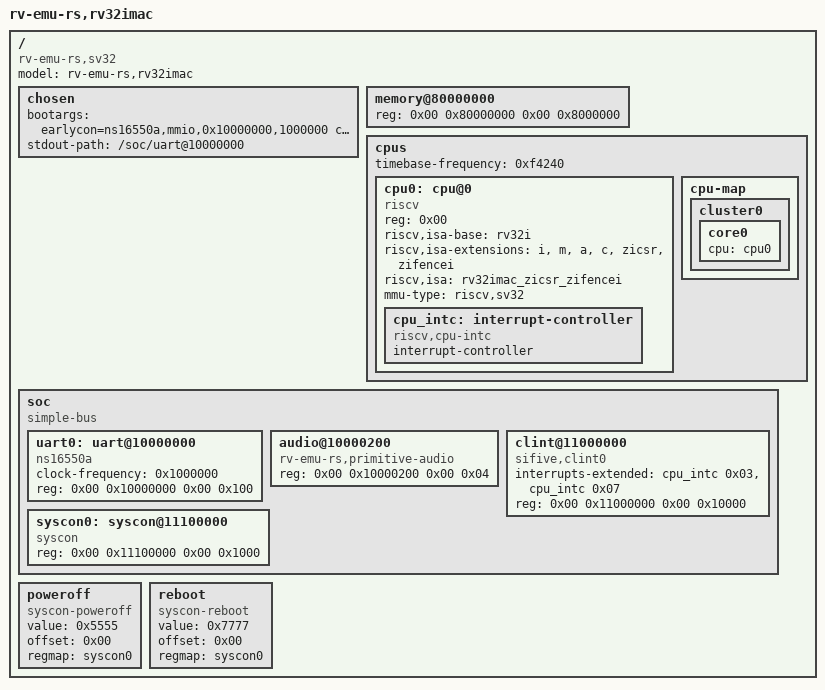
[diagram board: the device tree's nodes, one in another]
/dts-v1/;

/*
 * S-mode device tree for rv-emu-rs: OpenSBI fw_jump + Linux Image.
 *
 * Memory map (src/bus.rs):
 *   0x10000000  UART, 16550-compatible registers at offsets 0-7
 *   0x10000200  audio
 *   0x11000000  CLINT: msip at 0x0, mtimecmp at 0x4000, mtime at 0xbff8
 *   0x11100000  syscon: poweroff (0x5555) and reboot (0x7777)
 *   0x80000000  128 MiB RAM; the emulator places the DTB in the top 16 KiB
 *
 * There is no PLIC, so the UART node deliberately has no interrupts property:
 * the 8250 driver falls back to its timer-based polling mode.
 *
 * Build with: dtc -I dts -O dtb -o rv-emu-rs-sv32.dtb rv-emu-rs-sv32.dts
 */

/ {
    #address-cells = <0x02>;
    #size-cells = <0x02>;
    compatible = "rv-emu-rs,sv32";
    model = "rv-emu-rs,rv32imac";

    chosen {
        bootargs = "earlycon=ns16550a,mmio,0x10000000,1000000 console=ttyS0";
        stdout-path = "/soc/uart@10000000";
    };

    memory@80000000 {
        device_type = "memory";
        reg = <0x00 0x80000000 0x00 0x8000000>;
    };

    cpus {
        #address-cells = <0x01>;
        #size-cells = <0x00>;

        /* Clint::mtime() counts microseconds */
        timebase-frequency = <0xf4240>;

        cpu0: cpu@0 {
            device_type = "cpu";
            reg = <0x00>;
            status = "okay";
            compatible = "riscv";
            riscv,isa-base = "rv32i";
            riscv,isa-extensions = "i", "m", "a", "c", "zicsr", "zifencei";
            riscv,isa = "rv32imac_zicsr_zifencei";
            mmu-type = "riscv,sv32";

            cpu_intc: interrupt-controller {
                #interrupt-cells = <0x01>;
                interrupt-controller;
                compatible = "riscv,cpu-intc";
            };
        };

        cpu-map {
            cluster0 {
                core0 {
                    cpu = <&cpu0>;
                };
            };
        };
    };

    soc {
        #address-cells = <0x02>;
        #size-cells = <0x02>;
        compatible = "simple-bus";
        ranges;

        uart0: uart@10000000 {
            clock-frequency = <0x1000000>;
            reg = <0x00 0x10000000 0x00 0x100>;
            compatible = "ns16550a";
        };

        audio@10000200 {
            reg = <0x00 0x10000200 0x00 0x04>;
            compatible = "rv-emu-rs,primitive-audio";
        };

        clint@11000000 {
            interrupts-extended = <&cpu_intc 0x03 &cpu_intc 0x07>;
            reg = <0x00 0x11000000 0x00 0x10000>;
            compatible = "sifive,clint0", "riscv,clint0";
        };

        syscon0: syscon@11100000 {
            reg = <0x00 0x11100000 0x00 0x1000>;
            compatible = "syscon";
        };

    };

    poweroff {
        value = <0x5555>;
        offset = <0x00>;
        regmap = <&syscon0>;
        compatible = "syscon-poweroff";
    };

    reboot {
        value = <0x7777>;
        offset = <0x00>;
        regmap = <&syscon0>;
        compatible = "syscon-reboot";
    };

};
